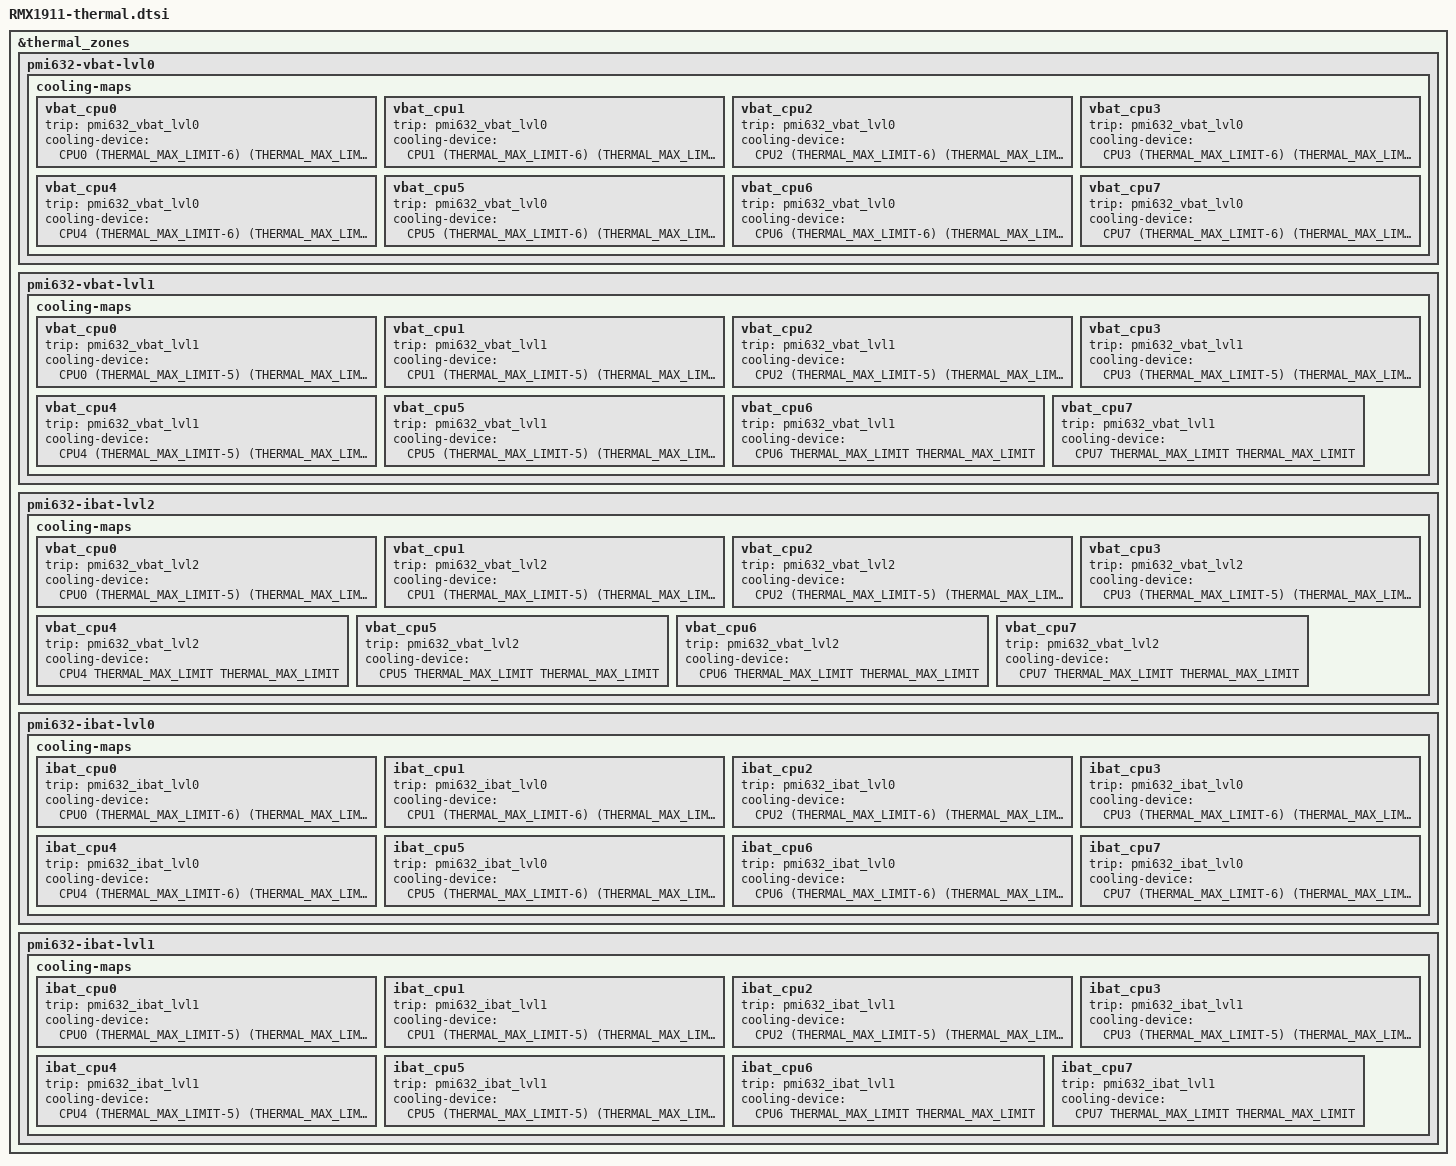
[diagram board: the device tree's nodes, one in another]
/*
 * Copyright (c) 2019, The Linux Foundation. All rights reserved.
 *
 * This program is free software; you can redistribute it and/or modify
 * it under the terms of the GNU General Public License version 2 and
 * only version 2 as published by the Free Software Foundation.
 *
 * This program is distributed in the hope that it will be useful,
 * but WITHOUT ANY WARRANTY; without even the implied warranty of
 * MERCHANTABILITY or FITNESS FOR A PARTICULAR PURPOSE.  See the
 * GNU General Public License for more details.
 */

&thermal_zones {
	/delete-property/ pmi632-bcl-lvl0;
        /delete-property/ pmi632-bcl-lvl1;
        /delete-property/ pmi632-bcl-lvl2;

	pmi632-vbat-lvl0 {
		cooling-maps {
			vbat_cpu0 {
				trip = <&pmi632_vbat_lvl0>;
				cooling-device =
					<&CPU0 (THERMAL_MAX_LIMIT-6)
						(THERMAL_MAX_LIMIT-6)>;
			};
			vbat_cpu1 {
				trip = <&pmi632_vbat_lvl0>;
				cooling-device =
					<&CPU1 (THERMAL_MAX_LIMIT-6)
						(THERMAL_MAX_LIMIT-6)>;
			};
			vbat_cpu2 {
				trip = <&pmi632_vbat_lvl0>;
				cooling-device =
					<&CPU2 (THERMAL_MAX_LIMIT-6)
						(THERMAL_MAX_LIMIT-6)>;
			};
			vbat_cpu3 {
				trip = <&pmi632_vbat_lvl0>;
				cooling-device =
					<&CPU3 (THERMAL_MAX_LIMIT-6)
						(THERMAL_MAX_LIMIT-6)>;
			};
			vbat_cpu4 {
				trip = <&pmi632_vbat_lvl0>;
				cooling-device =
					<&CPU4 (THERMAL_MAX_LIMIT-6)
						(THERMAL_MAX_LIMIT-6)>;
			};
			vbat_cpu5 {
				trip = <&pmi632_vbat_lvl0>;
				cooling-device =
					<&CPU5 (THERMAL_MAX_LIMIT-6)
						(THERMAL_MAX_LIMIT-6)>;
			};
			vbat_cpu6 {
				trip = <&pmi632_vbat_lvl0>;
				cooling-device =
					<&CPU6 (THERMAL_MAX_LIMIT-6)
						(THERMAL_MAX_LIMIT-6)>;
			};
			vbat_cpu7 {
				trip = <&pmi632_vbat_lvl0>;
				cooling-device =
					<&CPU7 (THERMAL_MAX_LIMIT-6)
						(THERMAL_MAX_LIMIT-6)>;
			};
		};
	};

	pmi632-vbat-lvl1 {
		cooling-maps {
			vbat_cpu0 {
				trip = <&pmi632_vbat_lvl1>;
				cooling-device =
					<&CPU0 (THERMAL_MAX_LIMIT-5)
						(THERMAL_MAX_LIMIT-5)>;
			};
			vbat_cpu1 {
				trip = <&pmi632_vbat_lvl1>;
				cooling-device =
					<&CPU1 (THERMAL_MAX_LIMIT-5)
						(THERMAL_MAX_LIMIT-5)>;
			};
			vbat_cpu2 {
				trip = <&pmi632_vbat_lvl1>;
				cooling-device =
					<&CPU2 (THERMAL_MAX_LIMIT-5)
						(THERMAL_MAX_LIMIT-5)>;
			};
			vbat_cpu3 {
				trip = <&pmi632_vbat_lvl1>;
				cooling-device =
					<&CPU3 (THERMAL_MAX_LIMIT-5)
						(THERMAL_MAX_LIMIT-5)>;
			};
			vbat_cpu4 {
				trip = <&pmi632_vbat_lvl1>;
				cooling-device =
					<&CPU4 (THERMAL_MAX_LIMIT-5)
						(THERMAL_MAX_LIMIT-5)>;
			};
			vbat_cpu5 {
				trip = <&pmi632_vbat_lvl1>;
				cooling-device =
					<&CPU5 (THERMAL_MAX_LIMIT-5)
						(THERMAL_MAX_LIMIT-5)>;
			};
			vbat_cpu6 {
				trip = <&pmi632_vbat_lvl1>;
				cooling-device =
					<&CPU6 THERMAL_MAX_LIMIT
						THERMAL_MAX_LIMIT>;
			};
			vbat_cpu7 {
				trip = <&pmi632_vbat_lvl1>;
				cooling-device =
					<&CPU7 THERMAL_MAX_LIMIT
						THERMAL_MAX_LIMIT>;
			};
		};
	};

	pmi632-ibat-lvl2 {
		cooling-maps {
			vbat_cpu0 {
				trip = <&pmi632_vbat_lvl2>;
				cooling-device =
					<&CPU0 (THERMAL_MAX_LIMIT-5)
						(THERMAL_MAX_LIMIT-5)>;
			};
			vbat_cpu1 {
				trip = <&pmi632_vbat_lvl2>;
				cooling-device =
					<&CPU1 (THERMAL_MAX_LIMIT-5)
						(THERMAL_MAX_LIMIT-5)>;
			};
			vbat_cpu2 {
				trip = <&pmi632_vbat_lvl2>;
				cooling-device =
					<&CPU2 (THERMAL_MAX_LIMIT-5)
						(THERMAL_MAX_LIMIT-5)>;
			};
			vbat_cpu3 {
				trip = <&pmi632_vbat_lvl2>;
				cooling-device =
					<&CPU3 (THERMAL_MAX_LIMIT-5)
						(THERMAL_MAX_LIMIT-5)>;
			};
			vbat_cpu4 {
				trip = <&pmi632_vbat_lvl2>;
				cooling-device =
					<&CPU4 THERMAL_MAX_LIMIT
						THERMAL_MAX_LIMIT>;
			};
			vbat_cpu5 {
				trip = <&pmi632_vbat_lvl2>;
				cooling-device =
					<&CPU5 THERMAL_MAX_LIMIT
						THERMAL_MAX_LIMIT>;
			};
			vbat_cpu6 {
				trip = <&pmi632_vbat_lvl2>;
				cooling-device =
					<&CPU6 THERMAL_MAX_LIMIT
						THERMAL_MAX_LIMIT>;
			};
			vbat_cpu7 {
				trip = <&pmi632_vbat_lvl2>;
				cooling-device =
					<&CPU7 THERMAL_MAX_LIMIT
						THERMAL_MAX_LIMIT>;
			};
		};
	};
	pmi632-ibat-lvl0 {
		cooling-maps {
			ibat_cpu0 {
				trip = <&pmi632_ibat_lvl0>;
				cooling-device =
					<&CPU0 (THERMAL_MAX_LIMIT-6)
						(THERMAL_MAX_LIMIT-6)>;
			};
			ibat_cpu1 {
				trip = <&pmi632_ibat_lvl0>;
				cooling-device =
					<&CPU1 (THERMAL_MAX_LIMIT-6)
						(THERMAL_MAX_LIMIT-6)>;
			};
			ibat_cpu2 {
				trip = <&pmi632_ibat_lvl0>;
				cooling-device =
					<&CPU2 (THERMAL_MAX_LIMIT-6)
						(THERMAL_MAX_LIMIT-6)>;
			};
			ibat_cpu3 {
				trip = <&pmi632_ibat_lvl0>;
				cooling-device =
					<&CPU3 (THERMAL_MAX_LIMIT-6)
						(THERMAL_MAX_LIMIT-6)>;
			};
			ibat_cpu4 {
				trip = <&pmi632_ibat_lvl0>;
				cooling-device =
					<&CPU4 (THERMAL_MAX_LIMIT-6)
						(THERMAL_MAX_LIMIT-6)>;
			};
			ibat_cpu5 {
				trip = <&pmi632_ibat_lvl0>;
				cooling-device =
					<&CPU5 (THERMAL_MAX_LIMIT-6)
						(THERMAL_MAX_LIMIT-6)>;
			};
			ibat_cpu6 {
				trip = <&pmi632_ibat_lvl0>;
				cooling-device =
					<&CPU6 (THERMAL_MAX_LIMIT-6)
						(THERMAL_MAX_LIMIT-6)>;
			};
			ibat_cpu7 {
				trip = <&pmi632_ibat_lvl0>;
				cooling-device =
					<&CPU7 (THERMAL_MAX_LIMIT-6)
						(THERMAL_MAX_LIMIT-6)>;
			};
		};
	};

	pmi632-ibat-lvl1 {
		cooling-maps {
			ibat_cpu0 {
				trip = <&pmi632_ibat_lvl1>;
				cooling-device =
					<&CPU0 (THERMAL_MAX_LIMIT-5)
						(THERMAL_MAX_LIMIT-5)>;
			};
			ibat_cpu1 {
				trip = <&pmi632_ibat_lvl1>;
				cooling-device =
					<&CPU1 (THERMAL_MAX_LIMIT-5)
						(THERMAL_MAX_LIMIT-5)>;
			};
			ibat_cpu2 {
				trip = <&pmi632_ibat_lvl1>;
				cooling-device =
					<&CPU2 (THERMAL_MAX_LIMIT-5)
						(THERMAL_MAX_LIMIT-5)>;
			};
			ibat_cpu3 {
				trip = <&pmi632_ibat_lvl1>;
				cooling-device =
					<&CPU3 (THERMAL_MAX_LIMIT-5)
						(THERMAL_MAX_LIMIT-5)>;
			};
			ibat_cpu4 {
				trip = <&pmi632_ibat_lvl1>;
				cooling-device =
					<&CPU4 (THERMAL_MAX_LIMIT-5)
						(THERMAL_MAX_LIMIT-5)>;
			};
			ibat_cpu5 {
				trip = <&pmi632_ibat_lvl1>;
				cooling-device =
					<&CPU5 (THERMAL_MAX_LIMIT-5)
						(THERMAL_MAX_LIMIT-5)>;
			};
			ibat_cpu6 {
				trip = <&pmi632_ibat_lvl1>;
				cooling-device =
					<&CPU6 THERMAL_MAX_LIMIT
						THERMAL_MAX_LIMIT>;
			};
			ibat_cpu7 {
				trip = <&pmi632_ibat_lvl1>;
				cooling-device =
					<&CPU7 THERMAL_MAX_LIMIT
						THERMAL_MAX_LIMIT>;
			};
		};
	};
};
